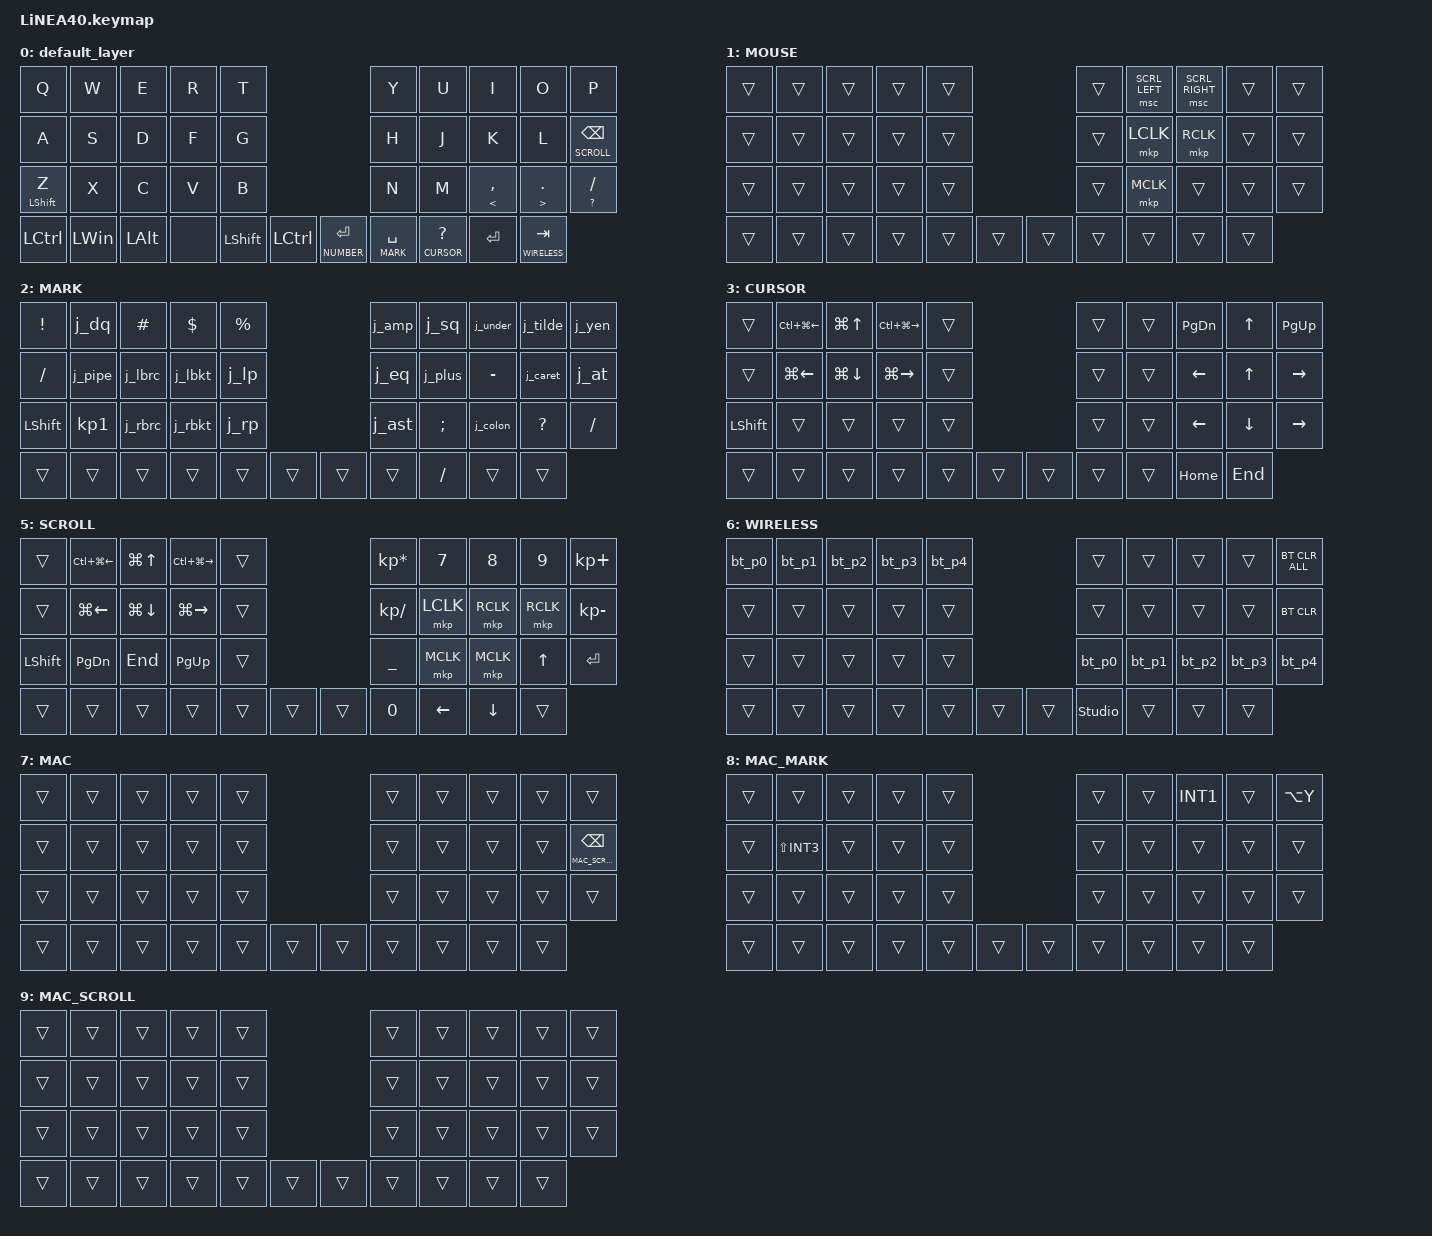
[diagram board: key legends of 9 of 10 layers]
#define ZMK_POINTING_DEFAULT_SCRL_VAL 100    //デフォルト150

#include <dt-bindings/zmk/input_transform.h>
#include <input/processors.dtsi>
#include <zephyr/dt-bindings/input/input-event-codes.h>
#include <behaviors.dtsi>
#include <dt-bindings/zmk/bt.h>
#include <dt-bindings/zmk/keys.h>
#include <dt-bindings/zmk/pointing.h>

#define MOUSE 1
#define MARK 2
#define CURSOR 3
#define NUMBER 4
#define SCROLL 5
#define WIRELESS 6
#define MAC 7
#define MAC_MARK 8
#define MAC_SCROLL 9

//mouse cursol

&mmv {
    delay-ms = <20>;
    trigger-period-ms = <5>;
    time-to-max-speed-ms = <100>;
    acceleration-exponent = <2>;
};

//mouse scroll

&msc {
    delay-ms = <3>;
    trigger-period-ms = <3>;
    time-to-max-speed-ms = <100>;
    acceleration-exponent = <0>;
};

/ {
    input_processors {
        zip_wheel_scaler: zip_wheel_scaler {
            compatible = "zmk,input-processor-scaler";
            #input-processor-cells = <2>;
            type = <INPUT_EV_REL>;
            codes = <INPUT_REL_WHEEL>;
            track-remainders;
        };

        pointer_accel_mac: pointer_accel_mac {
            compatible = "zmk,input-processor-acceleration";
            #input-processor-cells = <0>;
            input-type = <INPUT_EV_REL>;
            min-factor = <3000>;
            //小さくゆっくり動かした時は3倍にブースト(CPI200での減衰を打ち消し、元の感度に近づける)
            max-factor = <1000>;
            //大きく速く動かした時は等倍のまま(CPI200による減速をそのまま活かす)
            speed-threshold = <80>;
            speed-max = <400>;
            acceleration-exponent = <1>;
            track-remainders;
        };
    };
};

&msc_input_listener {
    speed_up {
        layers = <NUMBER>;
        input-processors = <&zip_wheel_scaler 3 1>; //スクロールを3倍速にする
    };
};

&trackball_listener {
    scroller {
        layers = <SCROLL MAC_SCROLL>;
        input-processors =
            <&zip_xy_transform INPUT_TRANSFORM_Y_INVERT>,
            //スクロール方向を逆転
            <&pointer_accel_mac>,
            //MAC_SCROLL(9)の生のXY移動のみ対象(SCROLLはドライバ側で既にWHEEL化済みのため無関係)。
            //小さい動きはブーストして追従性を出しつつ、大きい動きはCPI200の減速をそのまま活かす
            <&zip_xy_to_scroll_mapper>;
    };
};

/ {
    conditional_layers {
        compatible = "zmk,conditional-layers";
        mac_mark_layer {
            if-layers = <MAC MARK>;
            then-layer = <MAC_MARK>;
        };
    };
};

/ {
    combos {
        compatible = "zmk,combos";
        DeleteKey { bindings = <&kp DEL>; key-positions = <8 7>; };
        InsertKey { bindings = <&kp INS>; key-positions = <6 7>; };
        Enter { bindings = <&kp ENTER>; key-positions = <18 17 16>; };
        PrevClick { bindings = <&mkp MB4>; key-positions = <16 17>; };
        ClickNext { bindings = <&mkp MB5>; key-positions = <17 18>; };
        back { bindings = <&kp BACKSPACE>; key-positions = <8 9>; };
        screenshot { bindings = <&kp PRINTSCREEN>; key-positions = <4 3>; layers = <0 MOUSE MARK CURSOR NUMBER SCROLL WIRELESS>; };
        screenshot_mac { bindings = <&kp LG(LC(LS(N4)))>; key-positions = <4 3>; layers = <MAC>; };
        emoji { bindings = <&kp LG(PERIOD)>; key-positions = <3 1>; };
        escape { bindings = <&kp ESCAPE>; key-positions = <1 0>; };
        tab { bindings = <&kp TAB>; key-positions = <11 12>; };
        EN { bindings = <&kp LANG2>; key-positions = <12 13>; };
        JP { bindings = <&kp LANG1>; key-positions = <22 23>; };
        katakana { bindings = <&kp LANG3>; key-positions = <23 24>; };
    };

    behaviors {
        re_kp: sensor_rotate_kp {
            compatible = "zmk,behavior-sensor-rotate-var";
            #sensor-binding-cells = <2>;
            bindings = <&kp>, <&kp>;
        };

        mouse_scrl: mouse_wheel_scrl {
            compatible = "zmk,behavior-sensor-rotate-var";
            #sensor-binding-cells = <2>;
            bindings = <&msc>, <&msc>;

            tap-ms = <20>;
        };
    };

    /* --- 日本語JIS記号マクロ --- */
    macros {
        j_dq: j_dq { label = "DQ"; compatible = "zmk,behavior-macro"; #binding-cells = <0>; bindings = <&kp LS(N2)>; };
        j_amp: j_amp { label = "AMP"; compatible = "zmk,behavior-macro"; #binding-cells = <0>; bindings = <&kp LS(N6)>; };
        j_sq: j_sq { label = "SQ"; compatible = "zmk,behavior-macro"; #binding-cells = <0>; bindings = <&kp LS(N7)>; };
        j_eq: j_eq { label = "EQ"; compatible = "zmk,behavior-macro"; #binding-cells = <0>; bindings = <&kp LS(MINUS)>; };
        j_caret: j_cr { label = "CARET"; compatible = "zmk,behavior-macro"; #binding-cells = <0>; bindings = <&kp EQUAL>; };
        j_yen: j_yen { label = "YEN"; compatible = "zmk,behavior-macro"; #binding-cells = <0>; bindings = <&kp INT1>; };
        j_plus: j_plus { label = "PLUS"; compatible = "zmk,behavior-macro"; #binding-cells = <0>; bindings = <&kp COLON>; };
        j_tilde: j_tilde { label = "TILDE"; compatible = "zmk,behavior-macro"; #binding-cells = <0>; bindings = <&kp PLUS>; };
        j_pipe: j_pipe { label = "PIPE"; compatible = "zmk,behavior-macro"; #binding-cells = <0>; bindings = <&kp LS(INT1)>; };
        j_at: j_at { label = "AT"; compatible = "zmk,behavior-macro"; #binding-cells = <0>; bindings = <&kp LBKT>; };
        j_colon: j_colon { label = "COLON"; compatible = "zmk,behavior-macro"; #binding-cells = <0>; bindings = <&kp SQT>; };
        j_ast: j_ast { label = "AST"; compatible = "zmk,behavior-macro"; #binding-cells = <0>; bindings = <&kp LS(SQT)>; };
        j_bt: j_bt { label = "BT"; compatible = "zmk,behavior-macro"; #binding-cells = <0>; bindings = <&kp LS(RBKT)>; };
        j_under: j_under { label = "UNDER"; compatible = "zmk,behavior-macro"; #binding-cells = <0>; bindings = <&kp LS(INT1)>; };
        j_lbkt: j_lbkt { label = "L_BKT"; compatible = "zmk,behavior-macro"; #binding-cells = <0>; bindings = <&kp RBKT>; };
        j_rbkt: j_rbkt { label = "R_BKT"; compatible = "zmk,behavior-macro"; #binding-cells = <0>; bindings = <&kp BACKSLASH>; };
        j_lp: j_lp { label = "L_PAREN"; compatible = "zmk,behavior-macro"; #binding-cells = <0>; bindings = <&kp ASTRK>; };
        j_rp: j_rp { label = "R_PAREN"; compatible = "zmk,behavior-macro"; #binding-cells = <0>; bindings = <&kp LEFT_PARENTHESIS>; };
        j_lbrc: j_lbrc { label = "L_BRACE"; compatible = "zmk,behavior-macro"; #binding-cells = <0>; bindings = <&kp RIGHT_BRACE>; };
        j_rbrc: j_rbrc { label = "R_BRACE"; compatible = "zmk,behavior-macro"; #binding-cells = <0>; bindings = <&kp LS(BSLH)>; };

        /* BTプロファイル切替に連動してMacモード(MACレイヤー)をON/OFFする */
        bt_p0: bt_p0 { label = "BT_P0"; compatible = "zmk,behavior-macro"; #binding-cells = <0>; bindings = <&bt BT_SEL 0>, <&to 0>; };
        bt_p1: bt_p1 { label = "BT_P1"; compatible = "zmk,behavior-macro"; #binding-cells = <0>; bindings = <&bt BT_SEL 1>, <&to 0>; };
        bt_p2: bt_p2 { label = "BT_P2"; compatible = "zmk,behavior-macro"; #binding-cells = <0>; bindings = <&bt BT_SEL 2>, <&to 0>; };
        bt_p3: bt_p3 { label = "BT_P3"; compatible = "zmk,behavior-macro"; #binding-cells = <0>; bindings = <&bt BT_SEL 3>, <&to MAC>; };
        bt_p4: bt_p4 { label = "BT_P4"; compatible = "zmk,behavior-macro"; #binding-cells = <0>; bindings = <&bt BT_SEL 4>, <&to 0>; };
    };

    keymap {
        compatible = "zmk,keymap";

        default_layer {
            bindings = <
&kp Q             &kp W         &kp E         &kp R  &kp T                                     &kp Y         &kp U  &kp I                &kp O                    &kp P
&kp A             &kp S         &kp D         &kp F  &kp G                                     &kp H         &kp J  &kp K                &kp L                    &lt SCROLL BACKSPACE
&mt LEFT_SHIFT Z  &kp X         &kp C         &kp V  &kp B                                     &kp N         &kp M  &mt LESS_THAN COMMA  &mt GREATER_THAN PERIOD  &mt QUESTION SLASH
&kp LEFT_CONTROL  &kp LEFT_WIN  &kp LEFT_ALT  &none  &kp LEFT_SHIFT  &kp LCTRL    &lt NUMBER ENTER  &lt MARK SPACE          &lt CURSOR QUESTION       &kp ENTER                &lt WIRELESS TAB
            >;

            sensor-bindings = <&mouse_scrl SCRL_DOWN SCRL_UP>;
        };

        //1

        MOUSE {
            bindings = <
&trans  &trans  &trans  &trans  &trans                    &trans  &msc SCRL_LEFT  &msc SCRL_RIGHT  &trans  &trans
&trans  &trans  &trans  &trans  &trans                    &trans  &mkp LCLK        &mkp RCLK         &trans  &trans
&trans  &trans  &trans  &trans  &trans                    &trans  &mkp MCLK        &trans            &trans  &trans
&trans  &trans  &trans  &trans  &trans  &trans    &trans  &trans                    &trans            &trans  &trans
            >;
        };

        //2

        MARK {
            bindings = <
&kp EXCLAMATION  &j_dq            &kp HASH  &kp DOLLAR  &kp PERCENT                    &j_amp  &j_sq          &j_under   &j_tilde      &j_yen
&kp SLASH        &j_pipe          &j_lbrc   &j_lbkt     &j_lp                          &j_eq   &j_plus        &kp MINUS  &j_caret      &j_at
&kp LEFT_SHIFT   &kp KP_NUMBER_1  &j_rbrc   &j_rbkt     &j_rp                          &j_ast  &kp SEMICOLON  &j_colon   &kp QUESTION  &kp SLASH
&trans           &trans           &trans    &trans      &trans        &trans    &trans  &trans                   &kp SLASH  &trans        &trans
            >;

            sensor-bindings = <&re_kp C_VOLUME_DOWN C_VOLUME_UP>;
        };

        //3

        CURSOR {
            bindings = <
&trans          &kp LC(LG(LEFT_ARROW))  &kp LG(UP_ARROW)  &kp LC(LG(RIGHT_ARROW))  &trans                    &trans  &trans  &kp PG_DN        &kp UP_ARROW    &kp PG_UP
&trans          &kp LG(LEFT_ARROW)      &kp LG(DOWN)      &kp LG(RIGHT_ARROW)      &trans                    &trans  &trans  &kp LEFT_ARROW  &kp UP_ARROW    &kp RIGHT_ARROW
&kp LEFT_SHIFT  &trans                  &trans            &trans                   &trans                    &trans  &trans  &kp LEFT_ARROW  &kp DOWN_ARROW  &kp RIGHT_ARROW
&trans          &trans                  &trans            &trans                   &trans  &trans    &trans  &trans          &trans          &kp HOME        &kp END
            >;
        };

        //4

        NUMBER {
            bindings = <
&kp NUMBER_1  &kp NUMBER_2  &kp NUMBER_3  &kp NUMBER_4  &kp N5                              &kp NUMBER_6            &kp N7              &kp N8                   &kp N9  &kp N0
&kp F1        &kp F2        &kp F3        &kp F4        &kp F5                              &kp LG(LS(LEFT_ARROW))  &kp LG(UP_ARROW)    &kp LG(LS(RIGHT_ARROW))  &kp F9  &kp F10
&kp F6        &kp F7        &kp F8        &trans        &trans                              &kp LG(LEFT_ARROW)      &kp LG(DOWN_ARROW)  &kp LG(RIGHT_ARROW)      &trans  &trans
&trans        &trans        &trans        &trans        &kp INT_MUHENKAN  &trans    &trans  &trans                                                               &trans  &trans
            >;

            sensor-bindings = <&mouse_scrl SCRL_DOWN SCRL_UP>;
        };

        //5

        SCROLL {
            bindings = <
&trans          &kp LC(LG(LEFT_ARROW))  &kp LG(UP_ARROW)  &kp LC(LG(RIGHT_ARROW))  &trans                    &kp KP_MULTIPLY  &kp NUMBER_7  &kp NUMBER_8    &kp NUMBER_9    &kp KP_PLUS
&trans          &kp LG(LEFT_ARROW)      &kp LG(DOWN)      &kp LG(RIGHT_ARROW)      &trans                    &kp KP_SLASH     &mkp LCLK     &mkp RCLK       &mkp RCLK       &kp KP_MINUS
&kp LEFT_SHIFT  &kp PAGE_DOWN            &kp END           &kp PAGE_UP              &trans                    &kp UNDER        &mkp MCLK     &mkp MCLK       &kp UP_ARROW    &kp ENTER
&trans          &trans                  &trans            &trans                   &trans  &trans    &trans  &kp NUMBER_0                    &kp LEFT_ARROW  &kp DOWN_ARROW  &trans
            >;

            sensor-bindings = <&inc_dec_kp DOWN_ARROW UP_ARROW>;
        };

        //6

        WIRELESS {
            bindings = <
&bt_p0        &bt_p1        &bt_p2        &bt_p3        &bt_p4                         &trans &trans &trans &trans &bt BT_CLR_ALL
&trans        &trans        &trans        &trans        &trans                         &trans &trans &trans &trans &bt BT_CLR
&trans        &trans        &trans        &trans        &trans                         &bt_p0        &bt_p1        &bt_p2        &bt_p3        &bt_p4
&trans        &trans        &trans        &trans        &trans        &trans  &trans &studio_unlock        &trans &trans &trans
            >;

            sensor-bindings = <&inc_dec_kp RIGHT_ARROW LEFT_ARROW>;
        };

        //7

        MAC {
            bindings = <
&trans  &trans  &trans  &trans  &trans                    &trans  &trans  &trans  &trans  &trans
&trans  &trans  &trans  &trans  &trans                    &trans  &trans  &trans  &trans  &lt MAC_SCROLL BACKSPACE
&trans  &trans  &trans  &trans  &trans                    &trans  &trans  &trans  &trans  &trans
&trans  &trans  &trans  &trans  &trans  &trans    &trans  &trans          &trans  &trans  &trans
            >;
        };

        //8

        MAC_MARK {
            bindings = <
&trans  &trans  &trans  &trans  &trans                    &trans  &trans  &kp INT1  &trans  &kp LA(Y)
&trans  &kp LS(INT3)  &trans  &trans  &trans                    &trans  &trans  &trans  &trans  &trans
&trans  &trans  &trans  &trans  &trans                    &trans  &trans  &trans  &trans  &trans
&trans  &trans  &trans  &trans  &trans  &trans    &trans  &trans          &trans  &trans  &trans
            >;
        };

        //9

        MAC_SCROLL {
            bindings = <
&trans  &trans  &trans  &trans  &trans                    &trans  &trans  &trans  &trans  &trans
&trans  &trans  &trans  &trans  &trans                    &trans  &trans  &trans  &trans  &trans
&trans  &trans  &trans  &trans  &trans                    &trans  &trans  &trans  &trans  &trans
&trans  &trans  &trans  &trans  &trans  &trans    &trans  &trans          &trans  &trans  &trans
            >;
        };
    };
};
